AUTOSAR XML (schema 4-0-3)
package /ComponentTypes
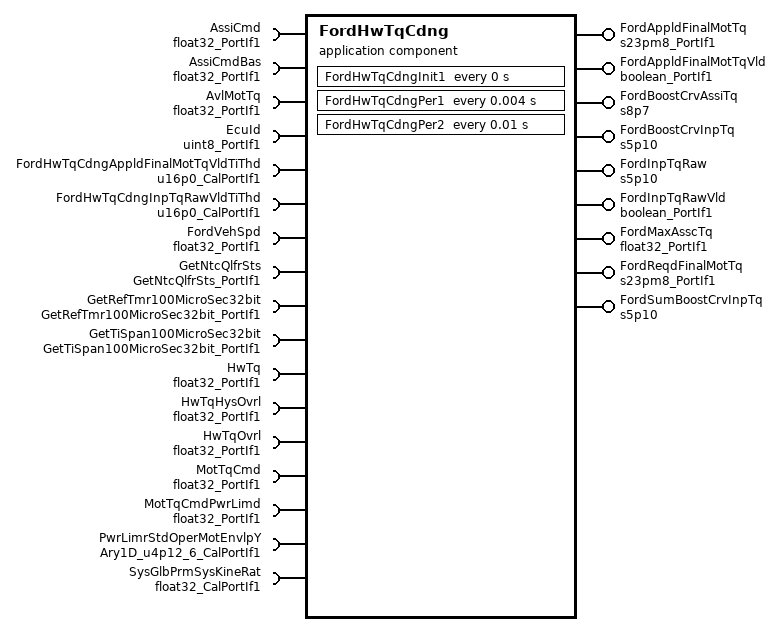
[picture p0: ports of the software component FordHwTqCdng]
  application sw component type FordHwTqCdng  # This function will output various torques in HWNm. It will also calculate an inverse boost curve and output a percent of available torque for Ford In House Features.
    9 x provide port:
      FordAppldFinalMotTq: nonqueued-sender-com-spec{data-element=Val, init-value=0}, provided-interface=s23pm8_PortIf1
      FordAppldFinalMotTqVld: nonqueued-sender-com-spec{data-element=Logl, init-value=0}, provided-interface=boolean_PortIf1  # This signal checks the validity of Applied Final Motor Torque
      FordBoostCrvAssiTq: nonqueued-sender-com-spec{data-element=Val, init-value=0}, provided-interface=s8p7
      FordBoostCrvInpTq: nonqueued-sender-com-spec{data-element=Val, init-value=0}, provided-interface=s5p10
      FordInpTqRaw: nonqueued-sender-com-spec{data-element=Val, init-value=0}, provided-interface=s5p10
      FordInpTqRawVld: nonqueued-sender-com-spec{data-element=Logl, init-value=0}, provided-interface=boolean_PortIf1  # This signal checks the validity of Input Torque Raw
      FordMaxAsscTq: nonqueued-sender-com-spec{data-element=Val, init-value=0}, provided-interface=float32_PortIf1
      FordReqdFinalMotTq: nonqueued-sender-com-spec{data-element=Val, init-value=0}, provided-interface=s23pm8_PortIf1
      FordSumBoostCrvInpTq: nonqueued-sender-com-spec{data-element=Val, init-value=0}, provided-interface=s5p10
    17 x require port:
      AssiCmd: nonqueued-receiver-com-spec{data-element=Val, filter=data-filter-type=ALWAYS, init-value=0}, required-interface=float32_PortIf1  # Assist Command used to display Filtered Boost Curve Assist Torque
      AssiCmdBas: nonqueued-receiver-com-spec{data-element=Val, filter=data-filter-type=ALWAYS, init-value=0}, required-interface=float32_PortIf1  # Assist Command Base used to calculate Boost Curve Input Torque
      AvlMotTq: nonqueued-receiver-com-spec{data-element=Val, filter=data-filter-type=ALWAYS, init-value=0}, required-interface=float32_PortIf1
      EcuId: nonqueued-receiver-com-spec{data-element=Val, filter=data-filter-type=ALWAYS, init-value=0}, required-interface=uint8_PortIf1
      FordHwTqCdngAppldFinalMotTqVldTiThd: parameter-require-com-spec{init-value=0, parameter=Val}, required-interface=u16p0_CalPortIf1  # Threshold to set Applied Final Motor Torque Valid
      FordHwTqCdngInpTqRawVldTiThd: parameter-require-com-spec{init-value=0, parameter=Val}, required-interface=u16p0_CalPortIf1  # Threshold to set Input Torque Raw Valid
      FordVehSpd: nonqueued-receiver-com-spec{data-element=Val, filter=data-filter-type=ALWAYS, init-value=0}, required-interface=float32_PortIf1  # Vehicle Speed is used to calculat Feature Direct BC Torque
      GetNtcQlfrSts: client-com-spec=Oper, required-interface=GetNtcQlfrSts_PortIf1  # Client defintion to return NTC state
      GetRefTmr100MicroSec32bit: client-com-spec=Oper, required-interface=GetRefTmr100MicroSec32bit_PortIf1  # It captures simulation time from the SimnTi value obtained at root layer of model and gives the RefTmr.
      GetTiSpan100MicroSec32bit: client-com-spec=Oper, required-interface=GetTiSpan100MicroSec32bit_PortIf1  # It Captures simulation time from SimnTi value, handles counter wrapping, and subtracts RefTmr, provides the TiSpan.
      HwTq: nonqueued-receiver-com-spec{data-element=Val, filter=data-filter-type=ALWAYS, init-value=0}, required-interface=float32_PortIf1  # Handwheel Torque is input to function Ford Handwheel Torque Conditioning used to calculate Boost Curve Input Torque
      HwTqHysOvrl: nonqueued-receiver-com-spec{data-element=Val, filter=data-filter-type=ALWAYS, init-value=0}, required-interface=float32_PortIf1  # Handwheel Torque Hysteresis Overlay is input to function Ford Handwheel Torque Conditioning used to calculate summed Boost Curve Input Torque
      HwTqOvrl: nonqueued-receiver-com-spec{data-element=Val, filter=data-filter-type=ALWAYS, init-value=0}, required-interface=float32_PortIf1  # Hysteresis Torque Overlay is input to function Ford Handwheel Torque Conditioning used to calculate summed Boost Curve Input Torque
      MotTqCmd: nonqueued-receiver-com-spec{data-element=Val, filter=data-filter-type=ALWAYS, init-value=0}, required-interface=float32_PortIf1  # Motor Torque Command is used to calculate Requested Final Motor Torque
      MotTqCmdPwrLimd: nonqueued-receiver-com-spec{data-element=Val, filter=data-filter-type=ALWAYS, init-value=0}, required-interface=float32_PortIf1  # Motor Torque Command Power Limited is used to calculate Applied Final Motor Torque
      PwrLimrStdOperMotEnvlpY: parameter-require-com-spec{init-value=[18973, 18973, 14553, 11989, 9011, 0], parameter=Ary1D}, required-interface=Ary1D_u4p12_6_CalPortIf1
      SysGlbPrmSysKineRat: parameter-require-com-spec{init-value=22, parameter=Val}, required-interface=float32_CalPortIf1  # SysGlbPrmSysKineRat is used to convert from Motor Newton Meters to Handwheel Newton Meters
    behavior FordHwTqCdng_InternalBehavior
      ar-typed-per-instance-memorys:
        data AppldFinalMotTqVldRefTi: sw-calibration-access=READ-ONLY, type=uint32  # Timer for Valid Reference Time will increment or reset based on the conditions
        data dFordHwTqCdngFildBoostCrvAssiTq: sw-calibration-access=READ-ONLY, type=float32  # Display Ford Handwheel Torque Conditioning Filtered Boost Curve Assist Torque
        data InpTqRawVldRefTi: sw-calibration-access=READ-ONLY, type=uint32  # Timer for Valid Reference Time will increment or reset based on the conditions
      timing event FordHwTqCdng_InitEvent: start-on-event=FordHwTqCdngInit1, period=0
      timing event TMT_FordHwTqCdngPer1: start-on-event=FordHwTqCdngPer1, period=0.004
      timing event TMT_FordHwTqCdngPer2: start-on-event=FordHwTqCdngPer2, period=0.01
      port-api-options:
        enable-take-address=false, indirect-api=false, port=AssiCmd
        enable-take-address=false, indirect-api=false, port=AssiCmdBas
        enable-take-address=false, indirect-api=false, port=AvlMotTq
        enable-take-address=false, indirect-api=false, port=EcuId
        enable-take-address=false, indirect-api=false, port=FordAppldFinalMotTq
        enable-take-address=false, indirect-api=false, port=FordAppldFinalMotTqVld
        enable-take-address=false, indirect-api=false, port=FordBoostCrvAssiTq
        enable-take-address=false, indirect-api=false, port=FordBoostCrvInpTq
        enable-take-address=false, indirect-api=false, port=FordHwTqCdngAppldFinalMotTqVldTiThd
        enable-take-address=false, indirect-api=false, port=FordHwTqCdngInpTqRawVldTiThd
        enable-take-address=false, indirect-api=false, port=FordInpTqRaw
        enable-take-address=false, indirect-api=false, port=FordInpTqRawVld
        enable-take-address=false, indirect-api=false, port=FordMaxAsscTq
        enable-take-address=false, indirect-api=false, port=FordReqdFinalMotTq
        enable-take-address=false, indirect-api=false, port=FordSumBoostCrvInpTq
        enable-take-address=false, indirect-api=false, port=FordVehSpd
        enable-take-address=false, indirect-api=false, port=GetNtcQlfrSts
        enable-take-address=false, indirect-api=false, port=GetRefTmr100MicroSec32bit
        enable-take-address=false, indirect-api=false, port=GetTiSpan100MicroSec32bit
        enable-take-address=false, indirect-api=false, port=HwTq
        enable-take-address=false, indirect-api=false, port=HwTqHysOvrl
        enable-take-address=false, indirect-api=false, port=HwTqOvrl
        enable-take-address=false, indirect-api=false, port=MotTqCmd
        enable-take-address=false, indirect-api=false, port=MotTqCmdPwrLimd
        enable-take-address=false, indirect-api=false, port=PwrLimrStdOperMotEnvlpY
        enable-take-address=false, indirect-api=false, port=SysGlbPrmSysKineRat
      runnable FordHwTqCdngInit1  # Initialization Runnable
        sync call SC_GetRefTmr100MicroSec32bit_Oper: operation=GetRefTmr100MicroSec32bit.Oper, timeout=0
      runnable FordHwTqCdngPer1  # Periodic Runnable at 4 millisecs
        data-receive-point-by-arguments:
          7 x access:
            REC_AssiCmdBas_Val: accessed-variable=AssiCmdBas.Val
            REC_AvlMotTq_Val: accessed-variable=AvlMotTq.Val
            REC_EcuId_Val: accessed-variable=EcuId.Val
            REC_FordVehSpd_Val: accessed-variable=FordVehSpd.Val
            REC_HwTq_Val: accessed-variable=HwTq.Val
            REC_HwTqHysOvrl_Val: accessed-variable=HwTqHysOvrl.Val
            REC_HwTqOvrl_Val: accessed-variable=HwTqOvrl.Val
        data-send-points:
          6 x access:
            SEND_FordBoostCrvAssiTq_Val: accessed-variable=FordBoostCrvAssiTq.Val
            SEND_FordBoostCrvInpTq_Val: accessed-variable=FordBoostCrvInpTq.Val
            SEND_FordInpTqRaw_Val: accessed-variable=FordInpTqRaw.Val
            SEND_FordInpTqRawVld_Logl: accessed-variable=FordInpTqRawVld.Logl
            SEND_FordMaxAsscTq_Val: accessed-variable=FordMaxAsscTq.Val
            SEND_FordSumBoostCrvInpTq_Val: accessed-variable=FordSumBoostCrvInpTq.Val
        sync call SC_GetNtcQlfrSts_Oper: operation=GetNtcQlfrSts.Oper, timeout=0
        sync call SC_GetRefTmr100MicroSec32bit_Oper: operation=GetRefTmr100MicroSec32bit.Oper, timeout=0
        sync call SC_GetTiSpan100MicroSec32bit_Oper: operation=GetTiSpan100MicroSec32bit.Oper, timeout=0
      runnable FordHwTqCdngPer2  # Periodic Runnable at 10 millisecs
        data-receive-point-by-arguments:
          4 x access:
            REC_AssiCmd_Val: accessed-variable=AssiCmd.Val
            REC_EcuId_Val: accessed-variable=EcuId.Val
            REC_MotTqCmd_Val: accessed-variable=MotTqCmd.Val
            REC_MotTqCmdPwrLimd_Val: accessed-variable=MotTqCmdPwrLimd.Val
        data-send-points:
          access SEND_FordAppldFinalMotTq_Val: accessed-variable=FordAppldFinalMotTq.Val
          access SEND_FordAppldFinalMotTqVld_Logl: accessed-variable=FordAppldFinalMotTqVld.Logl
          access SEND_FordReqdFinalMotTq_Val: accessed-variable=FordReqdFinalMotTq.Val
        sync call SC_GetNtcQlfrSts_Oper: operation=GetNtcQlfrSts.Oper, timeout=0
        sync call SC_GetRefTmr100MicroSec32bit_Oper: operation=GetRefTmr100MicroSec32bit.Oper, timeout=0
        sync call SC_GetTiSpan100MicroSec32bit_Oper: operation=GetTiSpan100MicroSec32bit.Oper, timeout=0
  swc implementation FordHwTqCdng_Implementation: behavior=FordHwTqCdng_InternalBehavior
    code-descriptors:
      code Default: artifact-descriptors=autosar-engineering-object={short-label=Default, category=SWSRC}
